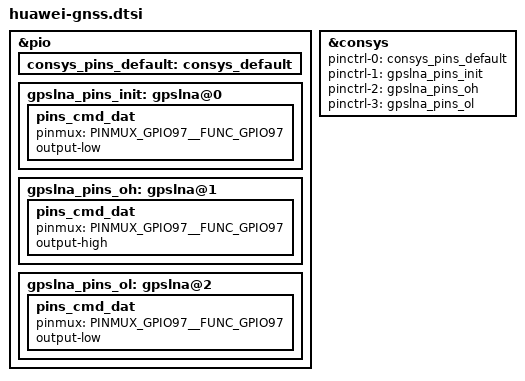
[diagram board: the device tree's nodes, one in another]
/* CONSYS GPIO standardization */
&pio {
	consys_pins_default: consys_default {
	};
	gpslna_pins_init: gpslna@0 {
		pins_cmd_dat {
			pinmux = <PINMUX_GPIO97__FUNC_GPIO97>;
			output-low;
		};
	};
	gpslna_pins_oh: gpslna@1 {
		pins_cmd_dat {
			pinmux = <PINMUX_GPIO97__FUNC_GPIO97>;
			output-high;
		};
	};
	gpslna_pins_ol: gpslna@2 {
		pins_cmd_dat {
			pinmux = <PINMUX_GPIO97__FUNC_GPIO97>;
			output-low;
		};
	};
};
&consys {
	pinctrl-names = "default", "gps_lna_state_init",
		"gps_lna_state_oh", "gps_lna_state_ol";
	pinctrl-0 = <&consys_pins_default>;
	pinctrl-1 = <&gpslna_pins_init>;
	pinctrl-2 = <&gpslna_pins_oh>;
	pinctrl-3 = <&gpslna_pins_ol>;
	status = "okay";
};
/* CONSYS end */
